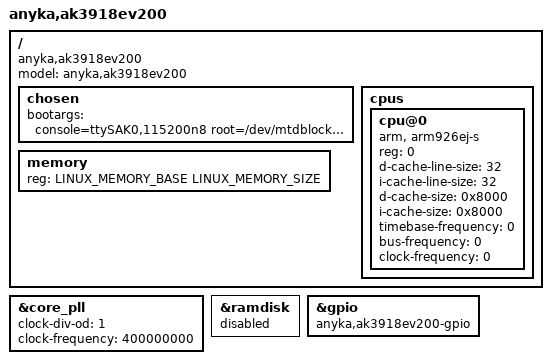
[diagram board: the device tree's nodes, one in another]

#include "anycloud_ak39ev330_common.dtsi"

#define LINUX_MEMORY_BASE     0x80000000
#define LINUX_MEMORY_SIZE     0x04000000

/ {
    model = "anyka,ak3918ev200";
    compatible = "anyka,ak3918ev200";

	chosen {
		bootargs = "console=ttySAK0,115200n8 root=/dev/mtdblock4 rootfstype=squashfs init=/sbin/akcam-preinit akcam.jffs=/dev/mtdblock5 mem=64M memsize=64M";
	};

	cpus {
	    #address-cells = <1>;
	    #size-cells = <0>;

	    cpu@0 {
	        compatible = "arm, arm926ej-s";
	        device_type = "cpu";
	        reg = <0>;
	        d-cache-line-size = <32>;
	        i-cache-line-size = <32>;
	        d-cache-size = <0x8000>;
	        i-cache-size = <0x8000>;
	        timebase-frequency = <0>;
	        bus-frequency = <0>;
	        clock-frequency = <0>;
	    };
	};

    memory {
	    device_type = "memory";
	    reg = <LINUX_MEMORY_BASE LINUX_MEMORY_SIZE>;
	};


};

&core_pll {
    clock-div-od = <1>;
    clock-frequency = <400000000>;
};

&ramdisk {
    /delete-property/ memory-region;
    status = "disabled";
};

&gpio {
    compatible = "anyka,ak3918ev200-gpio";
};
